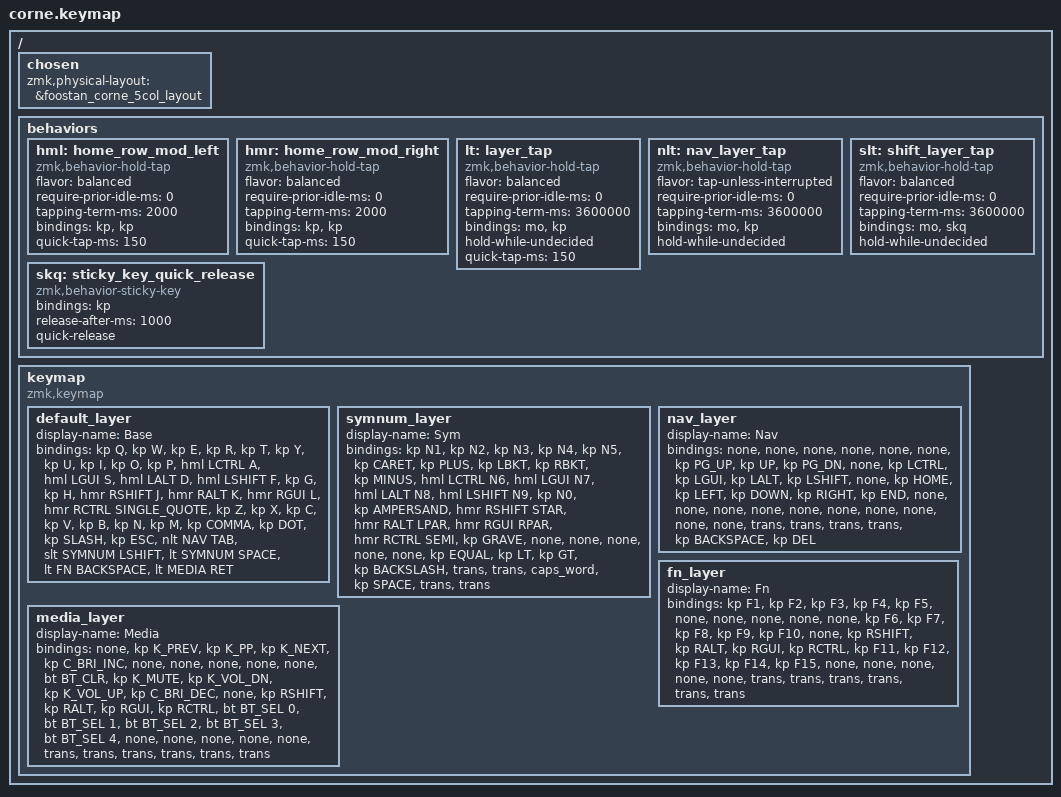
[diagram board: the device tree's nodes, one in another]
/*
 * Copyright (c) 2020 The ZMK Contributors
 *
 * SPDX-License-Identifier: MIT
 */

#include <behaviors.dtsi>
#include <dt-bindings/zmk/keys.h>
#include <dt-bindings/zmk/bt.h>

// layer menmonics
#define BASE 0
#define SYMNUM 1
#define NAV 2
#define FN 3
#define MEDIA 4

/ {
        chosen {
                zmk,physical-layout = &foostan_corne_5col_layout;
        };

        behaviors {
                hml: home_row_mod_left {
                        compatible = "zmk,behavior-hold-tap";
                        #binding-cells = <2>;
                        // balanced: require press and release of another key
                        // to interpret this key as a modifier.
                        flavor = "balanced";
                        require-prior-idle-ms = <0>;  // tried 200 but any idle really messes me up with SHIFT...
                        tapping-term-ms = <2000>;
                        bindings = <&kp>, <&kp>;

                        // // Prevent interpreting rolls as modifiers: modifier
                        // // only triggers when the modified key is the other hand, or thumb.
                        // hold-trigger-key-positions = <
                        //         //       0  1  2  3  4
                        //                  5  6  7  8  9
                        //         //      10 11 12 13 14
                        //                 15 16 17 18 19
                        //         //      20 21 22 23 24
                        //                 25 26 27 28 29
                        //                 30 31 32
                        //                 33 34 35
                        // >;
                        // hold-trigger-on-release;

                        quick-tap-ms = <150>;   // mash then hold for key repeat (wasd etc)
                };
                hmr: home_row_mod_right {
                        compatible = "zmk,behavior-hold-tap";
                        #binding-cells = <2>;
                        flavor = "balanced";
                        require-prior-idle-ms = <0>;  // tried 200 but any idle really messes me up with SHIFT...
                        tapping-term-ms = <2000>;
                        bindings = <&kp>, <&kp>;

                        // hold-trigger-key-positions = <
                        //         // Keys go left to right,
                        //         // so each run of 5 alternates hands.
                        //         // Thumbs at the end.
                        //                  0  1  2  3  4
                        //         //       5  6  7  8  9
                        //                 10 11 12 13 14
                        //         //      15 16 17 18 19
                        //                 20 21 22 23 24
                        //         //      25 26 27 28 29
                        //                 30 31 32
                        //                 33 34 35
                        // >;
                        // hold-trigger-on-release;

                        quick-tap-ms = <150>;   // mash then hold for key repeat (wasd etc)
                };
                lt: layer_tap {
                        compatible = "zmk,behavior-hold-tap";
                        #binding-cells = <2>;
                        // balanced requires a press-and-release of another key
                        // before it considers it a hold, which is good for spacebar
                        // which i tend to roll.
                        flavor = "balanced";
                        require-prior-idle-ms = <0>;
                        tapping-term-ms = <3600000>;
                        bindings = <&mo>, <&kp>;
                        hold-while-undecided;

                        quick-tap-ms = <150>;   // mash then hold for key repeat (backspace etc)
                };
                nlt: nav_layer_tap {
                        compatible = "zmk,behavior-hold-tap";
                        #binding-cells = <2>;
                        // tap-unless-interrupted considers tap of another key
                        // enough to be a hold, which is nice for arrow keys.
                        flavor = "tap-unless-interrupted";
                        require-prior-idle-ms = <0>;
                        tapping-term-ms = <3600000>;
                        bindings = <&mo>, <&kp>;
                        hold-while-undecided;
                };
                skq: sticky_key_quick_release {
                        compatible = "zmk,behavior-sticky-key";
                        #binding-cells = <1>;
                        bindings = <&kp>;
                        release-after-ms = <1000>;
                        quick-release;
                        // ignore-modifiers;
                };
                slt: shift_layer_tap {
                        // Press: apply Shift to the next key ("sticky keys").
                        // Hold: momentary layer.
                        compatible = "zmk,behavior-hold-tap";
                        #binding-cells = <2>;
                        flavor = "balanced";
                        require-prior-idle-ms = <0>;
                        tapping-term-ms = <3600000>;
                        bindings = <&mo>, <&skq>;
                        hold-while-undecided;
                };
        };
        keymap {
                compatible = "zmk,keymap";

                default_layer {
                        display-name = "Base";
                        bindings = <
                                //     q  w  e  r  t     y  u  i  o  p
                                //     a  s  d  f  g     h  j  k  l  '"
                                //     z  x  c  v  b     n  m  ,< .> /?

                                //          nav sym      num fn  media
                                //      esc tab shft     spc bks ret

                                &kp Q
                                &kp W
                                &kp E
                                &kp R
                                &kp T
                                &kp Y
                                &kp U
                                &kp I
                                &kp O
                                &kp P

                                &hml LCTRL      A
                                &hml LGUI       S
                                &hml LALT       D
                                &hml LSHIFT     F
                                &kp G
                                &kp H
                                &hmr RSHIFT     J
                                &hmr RALT       K
                                &hmr RGUI       L
                                &hmr RCTRL      SINGLE_QUOTE

                                &kp Z
                                &kp X
                                &kp C
                                &kp V
                                &kp B
                                &kp N
                                &kp M
                                &kp COMMA
                                &kp DOT
                                &kp SLASH

                                &kp ESC
                                &nlt NAV TAB
                                &slt SYMNUM LSHIFT

                                &lt SYMNUM SPACE
                                &lt FN BACKSPACE
                                &lt MEDIA RET
                        >;
                };
                symnum_layer {
                        display-name = "Sym";
                        bindings = <
                                //    1! 2@ 3# 4$ 5%            ^  +  [{ ]}  -_
                                //    6  7  8  9  0             &  *  (  )  ;:
                                //    `~ .  .  .  .                =  <  >  \|
                                //                                 
                                //          .  .  caps_word     .  .  .

                                &kp N1
                                &kp N2
                                &kp N3
                                &kp N4
                                &kp N5
                                &kp CARET
                                &kp PLUS
                                &kp LBKT
                                &kp RBKT
                                &kp MINUS

                                &hml LCTRL      N6
                                &hml LGUI       N7
                                &hml LALT       N8
                                &hml LSHIFT     N9
                                &kp N0
                                &kp AMPERSAND
                                &hmr RSHIFT     STAR
                                &hmr RALT       LPAR
                                &hmr RGUI       RPAR
                                &hmr RCTRL      SEMI

                                &kp GRAVE
                                &none
                                &none
                                &none
                                &none
                                &none
                                &kp EQUAL
                                &kp LT
                                &kp GT
                                &kp BACKSLASH

                                &trans
                                &trans
                                &caps_word
                                &kp SPACE     // to avoid cancelling the layer during sym-spc-sym rolls.
                                &trans
                                &trans
                        >;
                };
                nav_layer {
                        display-name = "Nav";
                        bindings = <
                                // Change backspace layer tap to plain backspace so it can repeat.
                                // Put del right next to it: good for quick edits.
                                //
                                //     .  .  .  .  .     .  pu ^  pd .
                                //     .  .  .  .  .     hm <  v  >  end
                                //     .  .  .  .  .     .  .  .  .  .
                                //
                                //           .  .  .     .  bks  del

                                &none
                                &none
                                &none
                                &none
                                &none
                                &none
                                &kp PG_UP
                                &kp UP
                                &kp PG_DN
                                &none

                                &kp LCTRL
                                &kp LGUI
                                &kp LALT
                                &kp LSHIFT
                                &none
                                &kp HOME
                                &kp LEFT
                                &kp DOWN
                                &kp RIGHT
                                &kp END

                                &none
                                &none
                                &none
                                &none
                                &none
                                &none
                                &none
                                &none
                                &none
                                &none

                                &trans
                                &trans
                                &trans
                                &trans
                                &kp BACKSPACE
                                &kp DEL
                        >;
                };
                fn_layer {
                        display-name = "Fn";
                        bindings = <
                                //      f1  f2  f3  f4  f5    .  .  .  .  .
                                //      f6  f7  f8  f9 f10    .  .  .  .  .
                                //     f11 f12 f13 f14 f15    .  .  .  .  .
                                //               .   .   .    .  .  .

                                &kp F1
                                &kp F2
                                &kp F3
                                &kp F4
                                &kp F5
                                &none
                                &none
                                &none
                                &none
                                &none

                                &kp F6
                                &kp F7
                                &kp F8
                                &kp F9
                                &kp F10
                                &none
                                &kp RSHIFT
                                &kp RALT
                                &kp RGUI
                                &kp RCTRL

                                &kp F11
                                &kp F12
                                &kp F13
                                &kp F14
                                &kp F15
                                &none
                                &none
                                &none
                                &none
                                &none

                                &trans
                                &trans
                                &trans
                                &trans
                                &trans
                                &trans
                        >;
                };
                media_layer {
                        display-name = "Media";
                        bindings = <
                                //     .  << |> >> br   .  .  .  .  .
                                //     bc m  -- ++ dm   .  .  .  .  .
                                //     b0 b1 b2 b3 b4   .  .  .  .  .
                                //           .  .  .    .  .  .

                                &none
                                &kp K_PREV
                                &kp K_PP
                                &kp K_NEXT
                                &kp C_BRI_INC
                                &none
                                &none
                                &none
                                &none
                                &none

                                &bt BT_CLR
                                &kp K_MUTE
                                &kp K_VOL_DN
                                &kp K_VOL_UP
                                &kp C_BRI_DEC
                                &none
                                &kp RSHIFT
                                &kp RALT
                                &kp RGUI
                                &kp RCTRL

                                &bt BT_SEL 0
                                &bt BT_SEL 1
                                &bt BT_SEL 2
                                &bt BT_SEL 3
                                &bt BT_SEL 4
                                &none
                                &none
                                &none
                                &none
                                &none

                                &trans
                                &trans
                                &trans
                                &trans
                                &trans
                                &trans
                        >;
                };
        };
};
